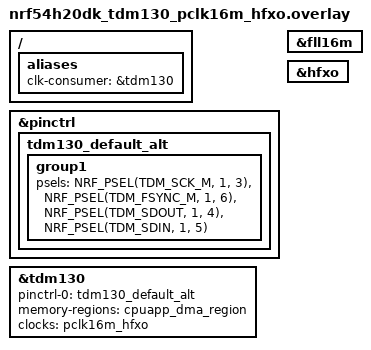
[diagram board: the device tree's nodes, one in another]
/*
 * Case: nRF54H20, tdm130 as the consumer, SCK/MCK on the 16 MHz peripheral clock (PCLK) with
 * fll16m driven from the HFXO for crystal accuracy.
 *
 * tdm130 is only used to carry the clock state; the sample does not operate the TDM. The single
 * pclk16m_hfxo state applies to both SCK and MCK: it maps to the PCLK mux position and names the
 * fll16m producer, requested so it locks to the HFXO.
 */
/ {
	aliases {
		clk-consumer = &tdm130;
	};
};

&pinctrl {
	tdm130_default_alt: tdm130_default_alt {
		group1 {
			psels = <NRF_PSEL(TDM_SCK_M, 1, 3)>,
				<NRF_PSEL(TDM_FSYNC_M, 1, 6)>,
				<NRF_PSEL(TDM_SDOUT, 1, 4)>,
				<NRF_PSEL(TDM_SDIN, 1, 5)>;
		};
	};
};

&fll16m {
	status = "okay";
};

&hfxo {
	status = "okay";
};

&tdm130 {
	status = "okay";
	pinctrl-0 = <&tdm130_default_alt>;
	pinctrl-names = "default";
	memory-regions = <&cpuapp_dma_region>;
	clocks = <&pclk16m_hfxo>;
};
